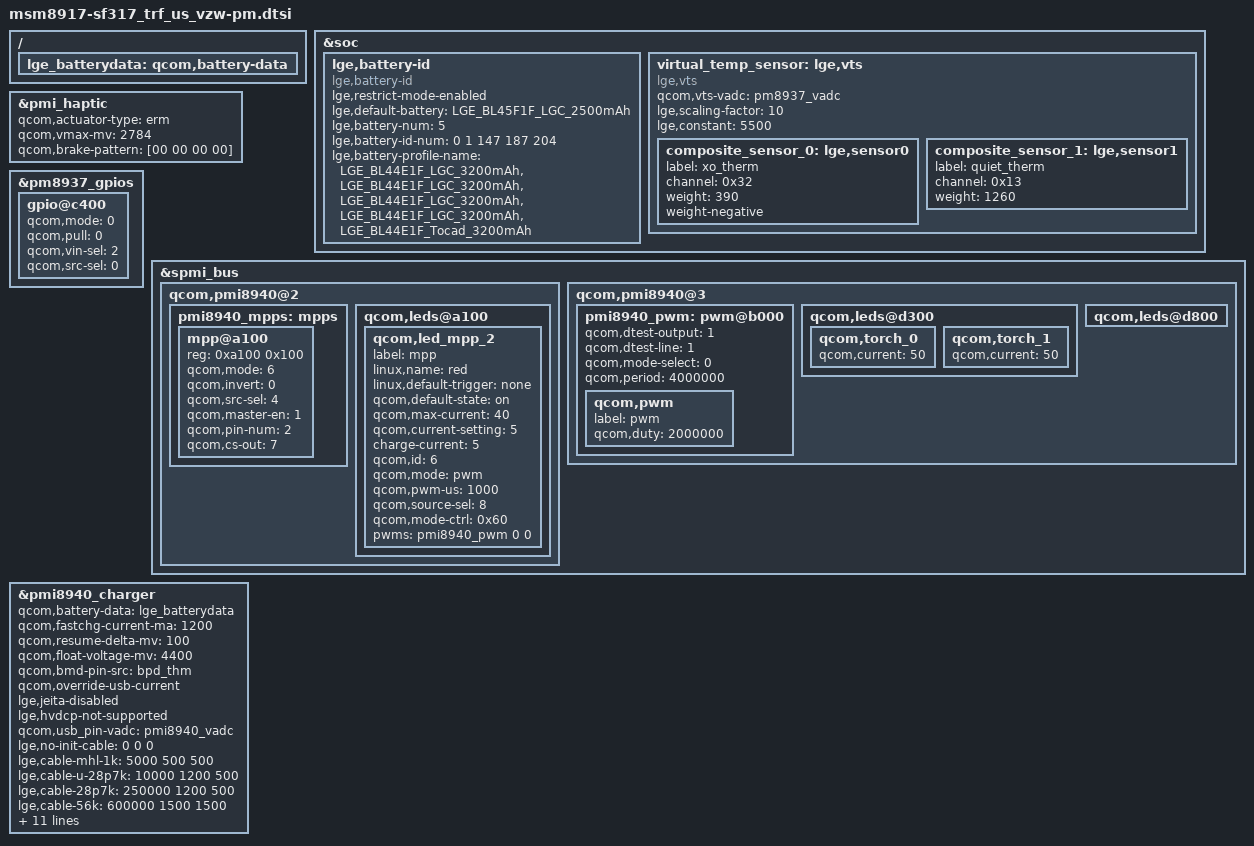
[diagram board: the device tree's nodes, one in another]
/*
 * Copyright (c) 2016, The Linux Foundation. All rights reserved.
 *
 * This program is free software; you can redistribute it and/or modify
 * it under the terms of the GNU General Public License version 2 and
 * only version 2 as published by the Free Software Foundation.
 *
 * This program is distributed in the hope that it will be useful,
 * but WITHOUT ANY WARRANTY; without even the implied warranty of
 * MERCHANTABILITY or FITNESS FOR A PARTICULAR PURPOSE.  See the
 * GNU General Public License for more details.
 */

/{
    lge_batterydata: qcom,battery-data {
         #include "../battery_profile/LGE_BL44E1F_LGC_3200mAh.dtsi"
         #include "../battery_profile/LGE_BL44E1F_Tocad_3200mAh.dtsi"
    };
};

&soc {
	lge,battery-id{
		compatible = "lge,battery-id";
		lge,restrict-mode-enabled;
		/*default battery profile*/
		lge,default-battery = "LGE_BL45F1F_LGC_2500mAh";
		/*Total number of combined of battery cell and battery id */
		lge,battery-num = <5>;
		/* battery id and battery profile match numbers */
		lge,battery-id-num = <0 1 147 187 204>;
		/* battery profile */
		lge,battery-profile-name = "LGE_BL44E1F_LGC_3200mAh",
						"LGE_BL44E1F_LGC_3200mAh",
						"LGE_BL44E1F_LGC_3200mAh",
						"LGE_BL44E1F_LGC_3200mAh",
						"LGE_BL44E1F_Tocad_3200mAh";
	};

	/* vts = (-0.39*xo_therm) + (1.26*quiet_therm) + 5.5 */
	virtual_temp_sensor: lge,vts {
		compatible = "lge,vts";
		qcom,vts-vadc = <&pm8937_vadc>;
		lge,scaling-factor= <10>;
		lge,constant = <5500>;
		composite_sensor_0: lge,sensor0 {
			label = "xo_therm";
			channel = <0x32>;
			weight = <390>;
			weight-negative;
		};
		composite_sensor_1: lge,sensor1 {
			label = "quiet_therm";
			channel = <0x13>;
			weight = <1260>;
		};
	};
};

&pmi_haptic{
	status = "okay";
	qcom,actuator-type = "erm";
	qcom,vmax-mv = <2784>;
	qcom,brake-pattern = [00 00 00 00];
};

&pm8937_gpios {
	gpio@c400 {
		qcom,mode = <0>;
		qcom,pull = <0>;
		qcom,vin-sel = <2>;
		qcom,src-sel = <0>;
		status = "okay";
	};
};

&spmi_bus {
	qcom,pmi8940@2 {
		pmi8940_mpps: mpps {
			mpp@a100 {
				status = "okay";
				reg = <0xa100 0x100>;
				qcom,mode = <6>;
				qcom,invert = <0>;
				qcom,src-sel = <4>;
				qcom,master-en = <1>;
				qcom,pin-num = <2>;
				qcom,cs-out = <7>;
			};
		};
		qcom,leds@a100 {
			status = "okay";
			qcom,led_mpp_2 {
				label = "mpp";
				linux,name = "red";
				linux,default-trigger = "none";
				qcom,default-state = "on";
				qcom,max-current = <40>;
				qcom,current-setting = <5>;
				charge-current = <5>;
				qcom,id = <6>;
				qcom,mode = "pwm";
				qcom,pwm-us = <1000>;
				qcom,source-sel = <8>;
				qcom,mode-ctrl = <0x60>;
				pwms = <&pmi8940_pwm 0 0>;
			};
		};
	};

	qcom,pmi8940@3 {
		pmi8940_pwm: pwm@b000 {
			status = "ok";
			qcom,dtest-output = <1>;
			qcom,dtest-line = <1>;
			qcom,mode-select = <0>;
			qcom,period = <4000000>;
			qcom,pwm {
				label = "pwm";
				qcom,duty = <2000000>;
			};
		};
		qcom,leds@d300 {
			qcom,torch_0 {
				qcom,current = <50>;
			};
			qcom,torch_1 {
				qcom,current = <50>;
			};
		};
		qcom,leds@d800 {
			/delete-property/ qcom,en-ext-pfet-sc-pro;
		};
	};
};

&pmi8940_charger {
	qcom,battery-data = <&lge_batterydata>;
	qcom,fastchg-current-ma = <1200>;
	qcom,resume-delta-mv = <100>;
	qcom,float-voltage-mv = <4400>;
	qcom,bmd-pin-src = "bpd_thm";
	qcom,override-usb-current;
	lge,jeita-disabled;
	lge,hvdcp-not-supported;

	qcom,usb_pin-vadc = <&pmi8940_vadc>;

	/* ref resistance 200K */
	lge,no-init-cable = <0 0 0>;
	lge,cable-mhl-1k = <5000 500 500>;
	lge,cable-u-28p7k = <10000 1200 500>;
	lge,cable-28p7k = <250000 1200 500>;
	lge,cable-56k = <600000 1500 1500>;
	lge,cable-100k = <620000 1200 500>;
	lge,cable-130k = <780000 1500 1500>;
	lge,cable-180k = <870000 1200 500>;
	lge,cable-200k = <910000 1200 500>;
	lge,cable-220k = <960000 1200 500>;
	lge,cable-270k = <1050000 1200 500>;
	lge,cable-330k = <1150000 1200 500>;
	lge,cable-620k = <1380000 1200 500>;
	lge,cable-910k = <1630000 1500 1500>;
	lge,cable-none = <1900000 1200  500>;

	lge,usb-max-current-ma = <1200>;
};
